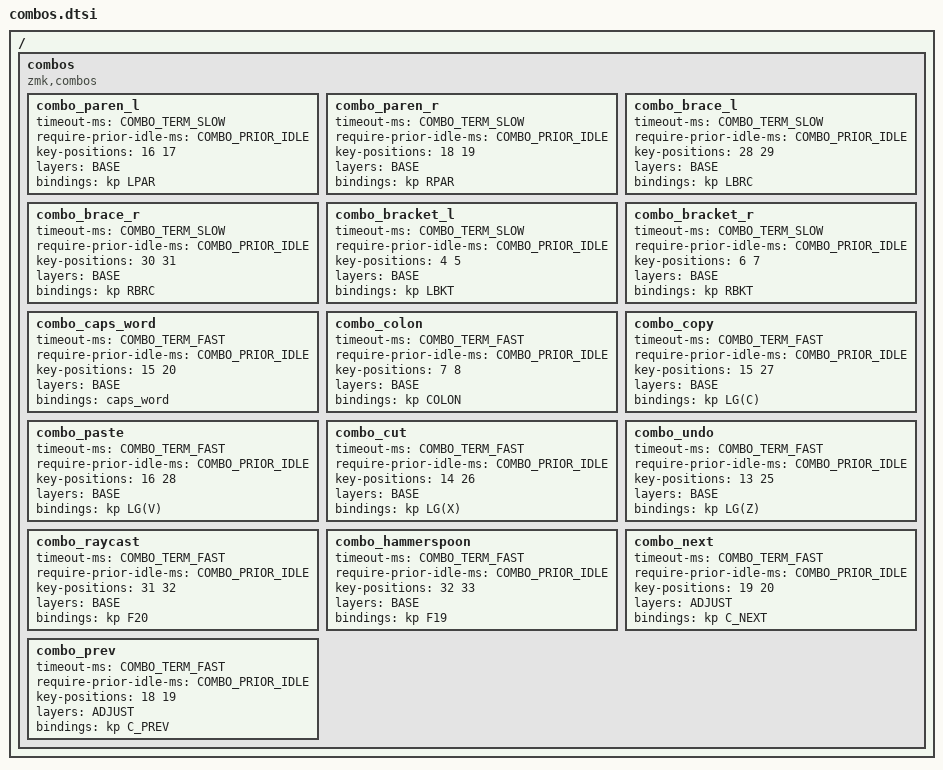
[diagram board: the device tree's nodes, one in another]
#define COMBO_TERM_FAST 35
#define COMBO_TERM_SLOW 45
#define COMBO_PRIOR_IDLE 100

/ {
    combos {
        compatible = "zmk,combos";

        // Caveats of the parenthesis combos:
        // 1. It interfers with mashing the home row to trigger "hyper" (or even just ctrl+shift).
        //    However, I have hyper bound to the inner home row to use instead.
        combo_paren_l {
            timeout-ms = <COMBO_TERM_SLOW>;
            require-prior-idle-ms = <COMBO_PRIOR_IDLE>;
            key-positions = <16 17>; // F+G
            layers = <BASE>;
            bindings = <&kp LPAR>;
        };
        combo_paren_r {
            timeout-ms = <COMBO_TERM_SLOW>;
            require-prior-idle-ms = <COMBO_PRIOR_IDLE>;
            key-positions = <18 19>; // H+J
            layers = <BASE>;
            bindings = <&kp RPAR>;
        };

        combo_brace_l {
            timeout-ms = <COMBO_TERM_SLOW>;
            require-prior-idle-ms = <COMBO_PRIOR_IDLE>;
            key-positions = <28 29>; // V+B
            layers = <BASE>;
            bindings = <&kp LBRC>;
        };
        combo_brace_r {
            timeout-ms = <COMBO_TERM_SLOW>;
            require-prior-idle-ms = <COMBO_PRIOR_IDLE>;
            key-positions = <30 31>; // N+M
            layers = <BASE>;
            bindings = <&kp RBRC>;
        };

        combo_bracket_l {
            timeout-ms = <COMBO_TERM_SLOW>;
            require-prior-idle-ms = <COMBO_PRIOR_IDLE>;
            key-positions = <4 5>; // R+T
            layers = <BASE>;
            bindings = <&kp LBKT>;
        };
        combo_bracket_r {
            timeout-ms = <COMBO_TERM_SLOW>;
            require-prior-idle-ms = <COMBO_PRIOR_IDLE>;
            key-positions = <6 7>; // Y+U
            layers = <BASE>;
            bindings = <&kp RBKT>;
        };

        combo_caps_word {
            timeout-ms = <COMBO_TERM_FAST>;
            require-prior-idle-ms = <COMBO_PRIOR_IDLE>;
            key-positions = <15 20>; // D+K
            layers = <BASE>;
            bindings = <&caps_word>;
        };

        combo_colon {
            timeout-ms = <COMBO_TERM_FAST>;
            require-prior-idle-ms = <COMBO_PRIOR_IDLE>;
            key-positions = <7 8>; // U+I
            layers = <BASE>;
            bindings = <&kp COLON>;
        };

        combo_copy {
            timeout-ms = <COMBO_TERM_FAST>;
            require-prior-idle-ms = <COMBO_PRIOR_IDLE>;
            key-positions = <15 27>; // D+C
            layers = <BASE>;
            bindings = <&kp LG(C)>;
        };
        combo_paste {
            timeout-ms = <COMBO_TERM_FAST>;
            require-prior-idle-ms = <COMBO_PRIOR_IDLE>;
            key-positions = <16 28>; // F+V
            layers = <BASE>;
            bindings = <&kp LG(V)>;
        };
        combo_cut {
            timeout-ms = <COMBO_TERM_FAST>;
            require-prior-idle-ms = <COMBO_PRIOR_IDLE>;
            key-positions = <14 26>; // S+X
            layers = <BASE>;
            bindings = <&kp LG(X)>;
        };
        combo_undo {
            timeout-ms = <COMBO_TERM_FAST>;
            require-prior-idle-ms = <COMBO_PRIOR_IDLE>;
            key-positions = <13 25>; // A+Z
            layers = <BASE>;
            bindings = <&kp LG(Z)>;
        };

        combo_raycast {
            timeout-ms = <COMBO_TERM_FAST>;
            require-prior-idle-ms = <COMBO_PRIOR_IDLE>;
            key-positions = <31 32>; // M+<
            layers = <BASE>;
            bindings = <&kp F20>;
        };
        combo_hammerspoon {
            timeout-ms = <COMBO_TERM_FAST>;
            require-prior-idle-ms = <COMBO_PRIOR_IDLE>;
            key-positions = <32 33>; // <+>
            layers = <BASE>;
            bindings = <&kp F19>;
        };

        combo_next {
            timeout-ms = <COMBO_TERM_FAST>;
            require-prior-idle-ms = <COMBO_PRIOR_IDLE>;
            key-positions = <19 20>; // J+K
            layers = <ADJUST>;
            bindings = <&kp C_NEXT>;
        };
        combo_prev {
            timeout-ms = <COMBO_TERM_FAST>;
            require-prior-idle-ms = <COMBO_PRIOR_IDLE>;
            key-positions = <18 19>; // H+J
            layers = <ADJUST>;
            bindings = <&kp C_PREV>;
        };
    };
};
// vi: ft=dts textwidth=0 noautoindent
